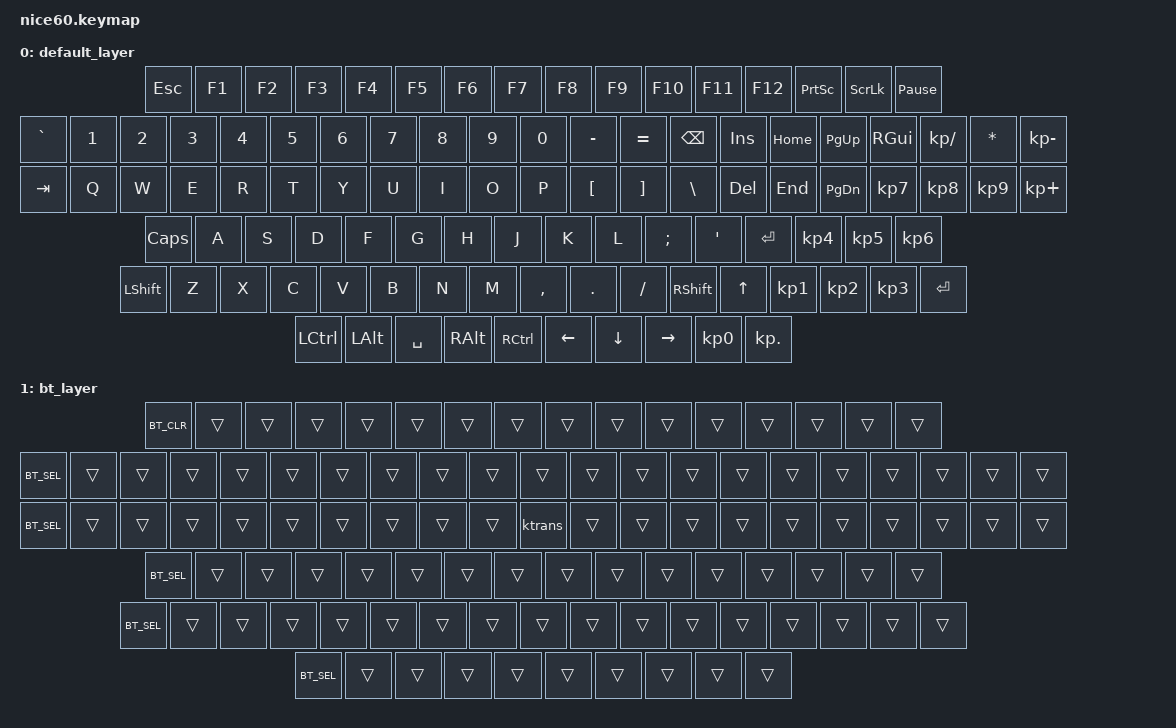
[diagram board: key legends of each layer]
/*
 * Copyright (c) 2021 Nick Winans
 *
 * SPDX-License-Identifier: MIT
 */

#include <behaviors.dtsi>
#include <dt-bindings/zmk/keys.h>
#include <dt-bindings/zmk/rgb.h>
#include <dt-bindings/zmk/bt.h>

/ {
    keymap {
        compatible = "zmk,keymap";

        default_layer {
// ------------------------------------------------------------------------------------------
// | ESC |  F1  |  F2  |  F3  |  F4  |  F5  |  F6  |  F7  |  F8  |  F9  |  F10  | F11 | F12 | PRT SCR | SLCK | PAUSE_BREAK |
// |  `  |  1  |  2  |  3  |  4  |  5  |  6  |  7  |  8  |  9  |  0  |  -  |  =  |   BKSP   | INSERT  |  HOME  |  PAGE_UP  |   WIN  | KP_SLASH | STAR | KP_MINUS |
// | TAB  |  Q  |  W  |  E  |  R  |  T  |  Y  |  U  |  I  |  O  |  P  |  [  |  ]  |   "|"   |  DELETE  |  END |  PAGE_DOWN |  KP_N7 |   KP_N8 | KP_N9 | KP_PLUS  |
// | CAPS  |  A  |  S  |  D  |  F  |  G  |  H  |  J  |  K  |  L  |  ;  |  '  |     ENTER    |                                 KP_N4 |   KP_N5 | KP_N6 |
// |  SHIFT  |  Z  |  X  |  C  |  V  |  B  |  N  |  M  |  ,  |  .  |  /  |      SHIFT       |              UP              |  KP_N1 |   KP_N2 | KP_N3 |    RET   |
// |  CTL      |  ALT  |            SPACE                                  |  ALT   |  CTL  |   LEFT  |  DOWN  |   RIGHT   |  KP_N0 |  KP_DOT |
// ------------------------------------------------------------------------------------------
            bindings = <
    &kp ESC   &kp F1   &kp F2   &kp F3   &kp F4    &kp F5   &kp F6   &kp F7   &kp F8  &kp F9  &kp F10  &kp F11  &kp F12  &kp PSCRN   &kp SLCK   &kp PAUSE_BREAK
    &kp GRAVE  &kp N1   &kp N2   &kp N3 &kp N4 &kp N5 &kp N6 &kp N7 &kp N8 &kp N9 &kp N0 &kp MINUS &kp EQUAL  &kp BSPC   &kp INS     &kp HOME   &kp PAGE_UP    &kp RGUI   &kp KP_SLASH   &kp STAR   &kp KP_MINUS
    &kp TAB   &kp Q    &kp W    &kp E  &kp R  &kp T  &kp Y  &kp U  &kp I  &kp O  &kp P  &kp LBKT  &kp RBKT  &kp BSLH     &kp DELETE  &kp END    &kp PAGE_DOWN  &kp KP_N7   &kp KP_N8    &kp KP_N9   &kp KP_PLUS
    &kp CLCK  &kp A    &kp S    &kp D  &kp F  &kp G  &kp H  &kp J  &kp K  &kp L  &kp SEMI &kp SQT            &kp RET                                           &kp KP_N4   &kp KP_N5    &kp KP_N6
    &kp LSHFT &kp Z    &kp X    &kp C  &kp V  &kp B  &kp N  &kp M  &kp COMMA &kp DOT &kp FSLH            &kp RSHFT                   &kp UP                    &kp KP_N1   &kp KP_N2    &kp KP_N3   &kp RET
    &kp LCTRL &kp LALT             &kp SPACE                     &kp RALT    &kp RCTRL                                   &kp LEFT    &kp DOWN   &kp RIGHT      &kp KP_N0                &kp KP_DOT  
            >;
        };
        bt_layer {
// ------------------------------------------------------------------------------------------
// |BT CLR|  F1  |  F2  |  F3  |  F4  |  F5  |  F6  |  F7  |  F8  |  F9  |  F10  | F11 | F12 | PRT SCR | SLCK | PAUSE_BREAK |
// |BT 1 |  1  |  2  |  3  |  4  |  5  |  6  |  7  |  8  |  9  |  0  |  -  |  =  |   BKSP   | INSERT  |  HOME  |  PAGE_UP  |   WIN  | KP_SLASH | STAR | KP_MINUS |
// | BT 2 |  Q  |  W  |  E  |  R  |  T  |  Y  |  U  |  I  |  O  |  P  |  [  |  ]  |   "|"   |  DELETE  |  END |  PAGE_DOWN |  KP_N7 |   KP_N8 | KP_N9 | KP_PLUS  |
// | BT 3  |  A  |  S  |  D  |  F  |  G  |  H  |  J  |  K  |  L  |  ;  |  '  |     ENTER    |                                 KP_N4 |   KP_N5 | KP_N6 |
// |  BT 4   |  Z  |  X  |  C  |  V  |  B  |  N  |  M  |  ,  |  .  |  /  |      SHIFT       |              UP              |  KP_N1 |   KP_N2 | KP_N3 |    RET   |
// |  BT 5     |  ALT  |            SPACE                                  |  ALT   |  CTL  |   LEFT  |  DOWN  |   RIGHT   |  KP_N0 |  KP_DOT |
// ------------------------------------------------------------------------------------------
            bindings = <
    &kp BT_CLR   &trans   &trans   &trans   &trans    &trans   &trans   &trans   &trans  &trans  &trans  &trans  &trans  &trans   &trans   &trans
    &kp BT_SEL 0  &trans   &trans   &trans &trans &trans &trans &trans &trans &trans &trans &trans &trans  &trans   &trans     &trans   &trans    &trans   &trans   &trans   &trans
    &kp BT_SEL 1  &trans    &trans    &trans  &trans  &trans  &trans  &trans  &trans  &trans  &ktrans  &trans  &trans  &trans     &trans  &trans    &trans  &trans   &trans    &trans   &trans
    &kp BT_SEL 2  &trans    &trans    &trans  &trans  &trans  &trans  &trans  &trans  &trans  &trans &trans            &trans                                           &trans   &trans    &trans
    &kp BT_SEL 3  &trans    &trans    &trans  &trans  &trans  &trans  &trans  &trans &trans &trans            &trans                   &trans                    &trans   &trans    &trans   &trans
    &kp BT_SEL 4  &trans             &trans                     &trans    &trans                                   &trans    &trans   &trans      &trans                &trans  
            >;
        };
    };
};
